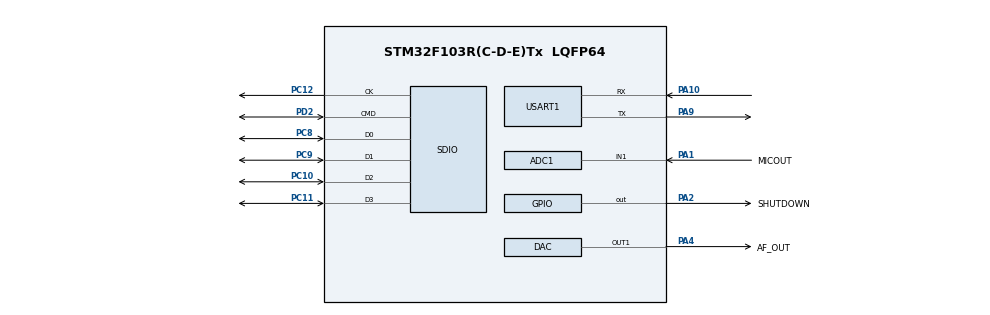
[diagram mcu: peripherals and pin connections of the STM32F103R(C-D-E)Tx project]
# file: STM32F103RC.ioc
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ADC1.Channel-4\#ChannelRegularConversion=ADC_CHANNEL_1
ADC1.NbrOfConversionFlag=1
ADC1.Rank-4\#ChannelRegularConversion=1
ADC1.SamplingTime-4\#ChannelRegularConversion=ADC_SAMPLETIME_1CYCLE_5
ADC1.master=1
FREERTOS.Tasks01=defaultTask,0,128,StartDefaultTask,Default,NULL,Dynamic,NULL,NULL
Mcu.Family=STM32F1
Mcu.Name=STM32F103R(C-D-E)Tx
Mcu.Package=LQFP64
NVIC.PriorityGroup=NVIC_PRIORITYGROUP_4
PA1.GPIO_Label=MICOUT
PA1.Signal=ADCx_IN1
PA10.Mode=Asynchronous
PA10.Signal=USART1_RX
PA13.Mode=Serial_Wire
PA13.Signal=SYS_JTMS-SWDIO
PA14.Mode=Serial_Wire
PA14.Signal=SYS_JTCK-SWCLK
PA2.GPIO_Label=SHUTDOWN
PA2.Signal=GPIO_Output
PA4.GPIO_Label=AF_OUT
PA4.Signal=COMP_DAC1_group
PA9.Mode=Asynchronous
PA9.Signal=USART1_TX
PC10.Mode=SD_4_bits_Wide_bus
PC10.Signal=SDIO_D2
PC11.Mode=SD_4_bits_Wide_bus
PC11.Signal=SDIO_D3
PC12.Mode=SD_4_bits_Wide_bus
PC12.Signal=SDIO_CK
PC8.Mode=SD_4_bits_Wide_bus
PC8.Signal=SDIO_D0
PC9.Mode=SD_4_bits_Wide_bus
PC9.Signal=SDIO_D1
PD2.Mode=SD_4_bits_Wide_bus
PD2.Signal=SDIO_CMD
ProjectManager.HeapSize=0x200
ProjectManager.StackSize=0x400
ProjectManager.TargetToolchain=MDK-ARM V5.32
RCC.APB1Freq_Value=8000000
RCC.APB2Freq_Value=8000000
SH.ADCx_IN1.0=ADC1_IN1,IN1
SH.COMP_DAC1_group.0=DAC_OUT1,DAC_OUT1
USART1.VirtualMode=VM_ASYNC
VP_FATFS_VS_SDIO.Mode=SDIO
VP_FREERTOS_VS_CMSIS_V1.Mode=CMSIS_V1
board=custom

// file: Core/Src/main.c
/* USER CODE BEGIN Header */
/**
  ******************************************************************************
  * @file           : main.c
  * @brief          : Main program body
  ******************************************************************************
  * @attention
  *
  * Copyright (c) 2024 STMicroelectronics.
  * All rights reserved.
  *
  * This software is licensed under terms that can be found in the LICENSE file
  * in the root directory of this software component.
  * If no LICENSE file comes with this software, it is provided AS-IS.
  *
  ******************************************************************************
  */
/* USER CODE END Header */
#include "main.h"
#include "cmsis_os.h"
#include "adc.h"
#include "dac.h"
#include "fatfs.h"
#include "sdio.h"
#include "usart.h"
#include "gpio.h"

void SystemClock_Config(void);
void MX_FREERTOS_Init(void);

int main(void)
{

  /* MCU Configuration--------------------------------------------------------*/

  /* Reset of all peripherals, Initializes the Flash interface and the Systick. */
  HAL_Init();

  /* Configure the system clock */
  SystemClock_Config();

  /* Initialize all configured peripherals */
  MX_GPIO_Init();
  MX_USART1_UART_Init();
  MX_ADC1_Init();
  MX_DAC_Init();
  MX_SDIO_SD_Init();
  MX_FATFS_Init();

  /* Call init function for freertos objects (in freertos.c) */
  MX_FREERTOS_Init();

  /* Start scheduler */
  osKernelStart();

  /* We should never get here as control is now taken by the scheduler */
  /* Infinite loop */
  while (1)
  {

  }
}

void SystemClock_Config(void)
{
  RCC_OscInitTypeDef RCC_OscInitStruct = {0};
  RCC_ClkInitTypeDef RCC_ClkInitStruct = {0};
  RCC_PeriphCLKInitTypeDef PeriphClkInit = {0};

  /** Initializes the RCC Oscillators according to the specified parameters
  * in the RCC_OscInitTypeDef structure.
  */
  RCC_OscInitStruct.OscillatorType = RCC_OSCILLATORTYPE_HSI;
  RCC_OscInitStruct.HSIState = RCC_HSI_ON;
  RCC_OscInitStruct.HSICalibrationValue = RCC_HSICALIBRATION_DEFAULT;
  RCC_OscInitStruct.PLL.PLLState = RCC_PLL_NONE;
  if (HAL_RCC_OscConfig(&RCC_OscInitStruct) != HAL_OK)
  {
    Error_Handler();
  }

  /** Initializes the CPU, AHB and APB buses clocks
  */
  RCC_ClkInitStruct.ClockType = RCC_CLOCKTYPE_HCLK|RCC_CLOCKTYPE_SYSCLK
                              |RCC_CLOCKTYPE_PCLK1|RCC_CLOCKTYPE_PCLK2;
  RCC_ClkInitStruct.SYSCLKSource = RCC_SYSCLKSOURCE_HSI;
  RCC_ClkInitStruct.AHBCLKDivider = RCC_SYSCLK_DIV1;
  RCC_ClkInitStruct.APB1CLKDivider = RCC_HCLK_DIV1;
  RCC_ClkInitStruct.APB2CLKDivider = RCC_HCLK_DIV1;

  if (HAL_RCC_ClockConfig(&RCC_ClkInitStruct, FLASH_LATENCY_0) != HAL_OK)
  {
    Error_Handler();
  }
  PeriphClkInit.PeriphClockSelection = RCC_PERIPHCLK_ADC;
  PeriphClkInit.AdcClockSelection = RCC_ADCPCLK2_DIV2;
  if (HAL_RCCEx_PeriphCLKConfig(&PeriphClkInit) != HAL_OK)
  {
    Error_Handler();
  }
}

void Error_Handler(void)
{
  __disable_irq();
  while (1)
  {
  }
}

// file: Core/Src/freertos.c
/* USER CODE BEGIN Header */
/**
  ******************************************************************************
  * File Name          : freertos.c
  * Description        : Code for freertos applications
  ******************************************************************************
  * @attention
  *
  * Copyright (c) 2024 STMicroelectronics.
  * All rights reserved.
  *
  * This software is licensed under terms that can be found in the LICENSE file
  * in the root directory of this software component.
  * If no LICENSE file comes with this software, it is provided AS-IS.
  *
  ******************************************************************************
  */
/* USER CODE END Header */

#include "FreeRTOS.h"
#include "task.h"
#include "main.h"
#include "cmsis_os.h"

/* USER CODE BEGIN Includes */
#include "../common.h"
/* USER CODE END Includes */

osThreadId defaultTaskHandle;

void StartDefaultTask(void const * argument);

void MX_FREERTOS_Init(void); /* (MISRA C 2004 rule 8.1) */

/* GetIdleTaskMemory prototype (linked to static allocation support) */
void vApplicationGetIdleTaskMemory( StaticTask_t **ppxIdleTaskTCBBuffer, StackType_t **ppxIdleTaskStackBuffer, uint32_t *pulIdleTaskStackSize );

/* USER CODE BEGIN GET_IDLE_TASK_MEMORY */
static StaticTask_t xIdleTaskTCBBuffer;
static StackType_t xIdleStack[configMINIMAL_STACK_SIZE];

void vApplicationGetIdleTaskMemory( StaticTask_t **ppxIdleTaskTCBBuffer, StackType_t **ppxIdleTaskStackBuffer, uint32_t *pulIdleTaskStackSize )
{
  *ppxIdleTaskTCBBuffer = &xIdleTaskTCBBuffer;
  *ppxIdleTaskStackBuffer = &xIdleStack[0];
  *pulIdleTaskStackSize = configMINIMAL_STACK_SIZE;
  /* place for user code */
}
/* USER CODE END GET_IDLE_TASK_MEMORY */

void MX_FREERTOS_Init(void) {

  /* Create the thread(s) */
  /* definition and creation of defaultTask */
  osThreadDef(defaultTask, StartDefaultTask, osPriorityNormal, 0, 128);
  defaultTaskHandle = osThreadCreate(osThread(defaultTask), NULL);

}

void StartDefaultTask(void const * argument)
{
  /* USER CODE BEGIN StartDefaultTask */
  printf("test\n");
  /* Infinite loop */
  for(;;)
  {
    osDelay(1);
  }
  /* USER CODE END StartDefaultTask */
}
